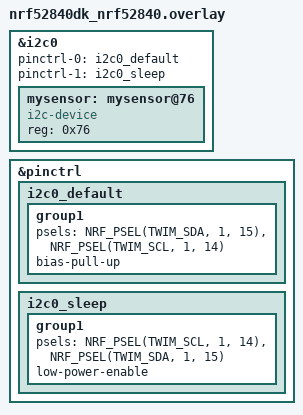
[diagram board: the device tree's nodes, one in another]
/* Step 5.2 Put an overlay content here */
&i2c0 {
    status = "okay";
    pinctrl-0 = <&i2c0_default>;
	pinctrl-1 = <&i2c0_sleep>;
    pinctrl-names = "default", "sleep";
    mysensor: mysensor@76{
        compatible = "i2c-device";
        status = "okay";
        reg = <0x76>;
    };
};

&pinctrl {
	/omit-if-no-ref/ i2c0_default: i2c0_default {
		group1  {
			psels = <NRF_PSEL(TWIM_SDA, 1, 15)>, <NRF_PSEL(TWIM_SCL, 1, 14)>;
			bias-pull-up;
		};
	};

	/omit-if-no-ref/ i2c0_sleep: i2c0_sleep {
		group1  {
			psels = <NRF_PSEL(TWIM_SCL, 1, 14)>,
					<NRF_PSEL(TWIM_SDA, 1, 15)>;
			low-power-enable;
		};
	};
};
